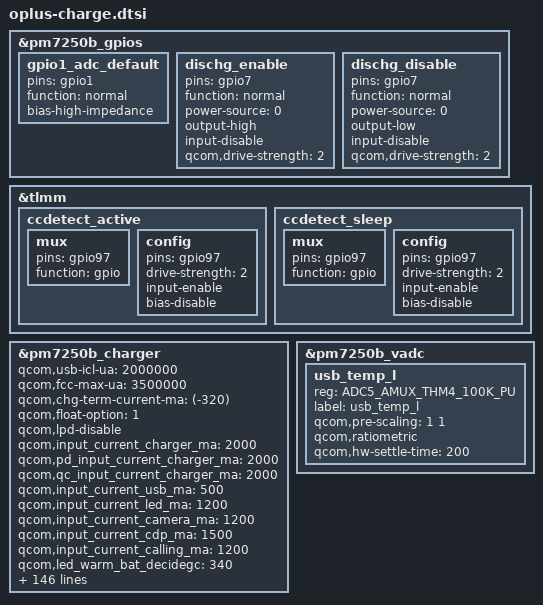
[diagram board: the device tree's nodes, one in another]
/**********************************************************************************
* Copyright (c)  2008-2019  Guangdong OPLUS Mobile Comm Corp., Ltd
* Description: OPLUS Charge Module Device Tree
*
* Version: 1.0
* Date: 2019-06-10
* Author: Yichun.Chen
*
* ------------------------------ Revision History: --------------------------------
* <version>           <date>                <author>                            <desc>
* Revision 1.0       2019-06-10            Yichun.Chen             Created for new architecture
***********************************************************************************/
&pm7250b_gpios {
	gpio1_adc_default: gpio1_adc_default {
		pins = "gpio1"; /* GPIO 1 */
		function = "normal"; /* normal */
		bias-high-impedance; /* DISABLE GPIO1 for ADC*/
	};

	dischg_enable: dischg_enable {
		pins = "gpio7";
		function = "normal";
		power-source = <0>;
		output-high;
		input-disable;
		qcom,drive-strength = <2>;
	};

	dischg_disable: dischg_disable {
		pins = "gpio7";
		function = "normal";
		power-source = <0>;
		output-low;
		input-disable;
		qcom,drive-strength = <2>;
	};
};

&tlmm {
	ccdetect_active: ccdetect_active {
		mux {
			pins = "gpio97";
			function = "gpio";
		};

		config {
			pins = "gpio97";
			drive-strength = <2>;
			input-enable;
			//bias-pull-up; /*PULL UP*/
			bias-disable;
		};
	};

	ccdetect_sleep: ccdetect_sleep {
		mux {
			pins = "gpio97";
			function = "gpio";
		};

		config {
			pins = "gpio97";
			drive-strength = <2>;
			//output-low;
			//bias-pull-down; /*PULL DOWN*/
			input-enable;
			bias-disable;
		};
	};
};

&pm7250b_charger {
	/* qcom options */
	qcom,usb-icl-ua = <2000000>;
	qcom,fcc-max-ua = <3500000>;
	qcom,chg-term-current-ma = <(-320)>;
	/*qcom,hvdcp-disable;*/
	qcom,float-option = <1>;
	qcom,lpd-disable;

	//for oplus chg framework:
	qcom,input_current_charger_ma = <2000>;
	qcom,pd_input_current_charger_ma = <2000>;
	qcom,qc_input_current_charger_ma = <2000>;
	qcom,input_current_usb_ma = <500>;
	qcom,input_current_led_ma = <1200>;
	qcom,input_current_camera_ma = <1200>;
	qcom,input_current_cdp_ma = <1500>;
	qcom,input_current_calling_ma = <1200>;
	
	qcom,led_warm_bat_decidegc = <340>;	/* 34C ~ 37C */
	qcom,led_high_bat_decidegc = <370>;	/* > 37C */
	qcom,input_current_led_ma_normal = <2000>;	/* <= 34C */
	qcom,input_current_led_ma_warm = <1500>;	/* 34C ~ 37C */
	qcom,input_current_led_ma_high = <1000>;	/* > 37C */

	qcom,iterm_ma = <260>; 			/* 0.05C + 10mA */
	qcom,recharge-mv = <100>;
	qcom,batt_capacity_mah = <4880>;	/* rated capacity */

	qcom,removed_bat_decidegc = <400>;	/* < -40C */

	qcom,cold_bat_decidegc = <20>;		/* -2C ~ 0C */
	qcom,temp_cold_vfloat_mv = <3980>;
	qcom,temp_cold_fastchg_current_ma = <350>;

	qcom,little_cold_bat_decidegc = <0>;	/* 0C ~ 5C */
	qcom,temp_little_cold_vfloat_mv = <4435>;
	qcom,temp_little_cold_fastchg_current_ma = <2350>;
	qcom,temp_little_cold_fastchg_current_ma_high = <2350>;
	qcom,temp_little_cold_fastchg_current_ma_low = <1400>;
	qcom,qc_temp_little_cold_fastchg_current_ma_high = <2350>;
	qcom,qc_temp_little_cold_fastchg_current_ma_low = <1400>;
	qcom,pd_temp_little_cold_fastchg_current_ma_high = <2350>;
	qcom,pd_temp_little_cold_fastchg_current_ma_low = <2350>;

	qcom,cool_bat_decidegc = <50>;		/* 5C~12C */
	qcom,temp_cool_vfloat_mv = <4435>;
	qcom,temp_cool_fastchg_current_ma_high = <2350>;
	qcom,temp_cool_fastchg_current_ma_low = <2350>;
	qcom,qc_temp_cool_fastchg_current_ma_high = <2350>;
	qcom,qc_temp_cool_fastchg_current_ma_low = <2350>;
	qcom,pd_temp_cool_fastchg_current_ma_high = <2350>;
	qcom,pd_temp_cool_fastchg_current_ma_low = <2350>;

	qcom,little_cool_bat_decidegc = <120>;	/* 12C ~ 16C */
	qcom,temp_little_cool_vfloat_mv = <4435>;
	qcom,temp_little_cool_fastchg_current_ma = <3350>;
	qcom,temp_little_cool_fastchg_current_ma_high = <3350>;
	qcom,temp_little_cool_fastchg_current_ma_low = <2350>;
	qcom,qc_temp_little_cool_fastchg_current_ma_high = <3350>;
	qcom,qc_temp_little_cool_fastchg_current_ma_low = <2350>;
	qcom,pd_temp_little_cool_fastchg_current_ma = <2100>;

	qcom,normal_bat_decidegc = <160>;	/* 16C ~ 45C */
	qcom,temp_normal_vfloat_mv = <4435>;
	qcom,temp_normal_fastchg_current_ma = <3350>;
	qcom,pd_temp_normal_fastchg_current_ma = <3350>;
	qcom,qc_temp_normal_fastchg_current_ma = <3350>;

	qcom,normal_phase1_bat_decidegc = <160>;       /* 16C ~ 22C */
	qcom,temp_normal_phase1_vfloat_mv = <4435>;
	qcom,temp_normal_phase1_fastchg_current_ma = <3180>;

	qcom,normal_phase2_bat_decidegc = <220>;       /* 22C ~ 34C */
	qcom,temp_normal_phase2_vfloat_mv = <4435>;
	qcom,temp_normal_phase2_fastchg_current_ma_high = <3350>;
	qcom,temp_normal_phase2_fastchg_current_ma_low = <3180>;

	qcom,normal_phase3_bat_decidegc = <320>;       /* 34 ~ 37C */
	qcom,temp_normal_phase3_vfloat_mv = <4435>;
	qcom,temp_normal_phase3_fastchg_current_ma_high = <2850>;
	qcom,temp_normal_phase3_fastchg_current_ma_low = <2850>;

	qcom,normal_phase4_bat_decidegc = <370>;       /* 37C ~ 40C */
	qcom,temp_normal_phase4_vfloat_mv = <4435>;
	qcom,temp_normal_phase4_fastchg_current_ma_high = <2500>;
	qcom,temp_normal_phase4_fastchg_current_ma_low = <2500>;

	qcom,normal_phase5_bat_decidegc = <400>;       /* 40C ~ 42C */
	qcom,temp_normal_phase5_vfloat_mv = <4435>;
	qcom,temp_normal_phase5_fastchg_current_ma = <2000>;

	qcom,normal_phase6_bat_decidegc = <420>;       /* 42C ~ 45C */
	qcom,temp_normal_phase6_vfloat_mv = <4435>;
	qcom,temp_normal_phase6_fastchg_current_ma = <1450>;
	
	qcom,warm_bat_decidegc = <450>;		/* 45C ~ 53C */
	qcom,temp_warm_vfloat_mv = <4130>;
	qcom,temp_warm_fastchg_current_ma = <1400>;
	qcom,temp_warm_fastchg_current_ma_led_on = <500>;
	qcom,qc_temp_warm_fastchg_current_ma = <1400>;
	qcom,pd_temp_warm_fastchg_current_ma = <1400>;

	qcom,hot_bat_decidegc = <500>;

	qcom,non_standard_vfloat_mv = <4435>;
	qcom,non_standard_fastchg_current_ma = <512>;
	qcom,short_c_bat_cv_mv = <4330>;
	qcom,short_c_bat_vfloat_mv = <3800>;
	qcom,short_c_bat_fastchg_current_ma = <512>;

	qcom,cold_vfloat_sw_limit = <3930>;
	qcom,little_cold_vfloat_sw_limit = <4385>;
	qcom,cool_vfloat_sw_limit = <4385>;
	qcom,little_cool_vfloat_sw_limit = <4385>;
	qcom,normal_vfloat_sw_limit = <4385>;
	qcom,warm_vfloat_sw_limit = <4080>;
	qcom,non_standard_vfloat_sw_limit = <4385>;
	qcom,short_c_bat_vfloat_sw_limit = <3750>;

	qcom,max_chg_time_sec = <72000>;
	qcom,charger_hv_thr = <10000>;
	qcom,charger_recv_thr = <9700>;
	qcom,charger_lv_thr = <3400>;
	qcom,vbatt_full_thr = <4400>;
	qcom,vbatt_hv_thr = <4550>;
	qcom,vfloat_step_mv = <10>;

	qcom,non_standard_vfloat_over_sw_limit = <4440>;
	qcom,cold_vfloat_over_sw_limit = <3985>;
	qcom,little_cold_vfloat_over_sw_limit = <4440>;
	qcom,cool_vfloat_over_sw_limit = <4440>;
	qcom,little_cool_vfloat_over_sw_limit = <4440>;
	qcom,normal_vfloat_over_sw_limit = <4440>;
	qcom,warm_vfloat_over_sw_limit = <4135>;

	qcom,vbatt_power_off = <3300>;
	qcom,vbatt_soc_1 = <3410>;
	qcom,vbatt_num = <1>;

	qcom,normal_vterm_hw_inc = <18>;
	qcom,non_normal_vterm_hw_inc = <18>;

	qcom,default_iterm_ma = <260>;
	qcom,default_temp_normal_fastchg_current_ma = <3350>;
	qcom,default_normal_vfloat_sw_limit = <4385>;
	qcom,default_temp_normal_vfloat_mv = <4435>;
	qcom,default_normal_vfloat_over_sw_limit = <4440>;

	qcom,offset_temp = <0>;
	qcom,check_batt_full_by_sw;
	qcom,chg_ctrl_by_lcd;
	qcom,chg_ctrl_by_calling;
	qcom,sw_vfloat_over_protect_enable;
	qcom,support_ccdetect;

	//for PD9V or QC9V
	qcom,vbatt_pdqc_to_5v_thr = <3400>;
	qcom,dual_charger_support = <1>;

	/* gpio options */
	qcom,dischg-gpio = <&pm7250b_gpios 7 0x00>;
	qcom,ccdetect-gpio = <&tlmm 97 0x00>;
	pinctrl-names = "dischg_enable", "dischg_disable", "gpio1_adc_default",
					"ccdetect_active", "ccdetect_sleep",
					"2uart_active", "2uart_sleep";
	pinctrl-0 = <&dischg_enable>;
	pinctrl-1 = <&dischg_disable>;
	pinctrl-2 = <&gpio1_adc_default>;
	pinctrl-3 = <&ccdetect_active>;
	pinctrl-4 = <&ccdetect_sleep>;
	pinctrl-5 = <&qupv3_se9_2uart_active>;
	pinctrl-6 = <&qupv3_se9_2uart_sleep>;
};

&pm7250b_vadc {
	/delete-node/ smb1390_therm;
	usb_temp_l {
		reg = <ADC5_AMUX_THM4_100K_PU>;
		label = "usb_temp_l";
		qcom,pre-scaling = <1 1>;
		qcom,ratiometric;
		qcom,hw-settle-time = <200>;
	};
};
